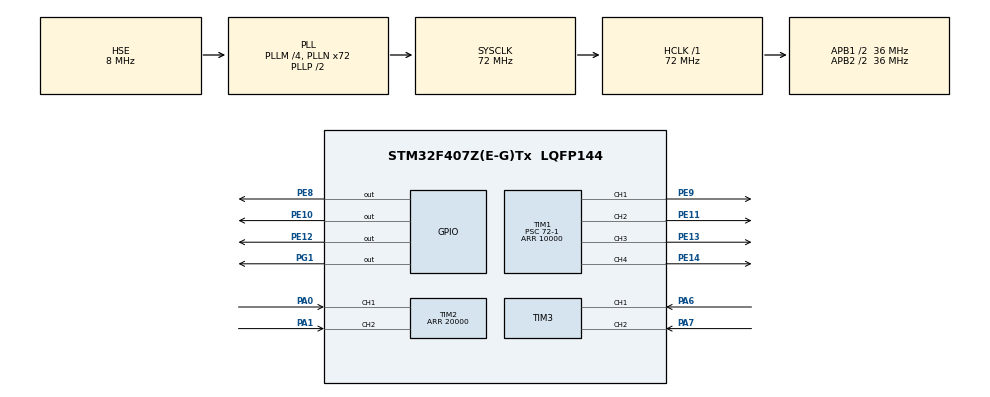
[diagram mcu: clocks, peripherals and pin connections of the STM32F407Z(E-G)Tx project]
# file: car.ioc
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Mcu.Family=STM32F4
Mcu.Name=STM32F407Z(E-G)Tx
Mcu.Package=LQFP144
NVIC.PriorityGroup=NVIC_PRIORITYGROUP_4
NVIC.TIM2_IRQn=true\:0\:0\:false\:false\:true\:true\:true\:true
NVIC.TIM6_DAC_IRQn=true\:1\:0\:true\:false\:true\:true\:true\:true
PA0-WKUP.Signal=S_TIM2_CH1_ETR
PA1.Signal=S_TIM2_CH2
PA13.Mode=Serial_Wire
PA13.Signal=SYS_JTMS-SWDIO
PA14.Mode=Serial_Wire
PA14.Signal=SYS_JTCK-SWCLK
PA6.Signal=S_TIM3_CH1
PA7.Signal=S_TIM3_CH2
PC14-OSC32_IN.Mode=LSE-External-Oscillator
PC14-OSC32_IN.Signal=RCC_OSC32_IN
PC15-OSC32_OUT.Mode=LSE-External-Oscillator
PC15-OSC32_OUT.Signal=RCC_OSC32_OUT
PE10.PinState=GPIO_PIN_SET
PE10.Signal=GPIO_Output
PE11.Signal=S_TIM1_CH2
PE12.PinState=GPIO_PIN_RESET
PE12.Signal=GPIO_Output
PE13.Signal=S_TIM1_CH3
PE14.Signal=S_TIM1_CH4
PE8.PinState=GPIO_PIN_RESET
PE8.Signal=GPIO_Output
PE9.Signal=S_TIM1_CH1
PG1.PinState=GPIO_PIN_SET
PG1.Signal=GPIO_Output
PH0-OSC_IN.Mode=HSE-External-Oscillator
PH0-OSC_IN.Signal=RCC_OSC_IN
PH1-OSC_OUT.Mode=HSE-External-Oscillator
PH1-OSC_OUT.Signal=RCC_OSC_OUT
ProjectManager.HeapSize=0x200
ProjectManager.StackSize=0x400
ProjectManager.TargetToolchain=MDK-ARM V5.32
RCC.48MHZClocksFreq_Value=36000000
RCC.AHBFreq_Value=72000000
RCC.APB1CLKDivider=RCC_HCLK_DIV2
RCC.APB1Freq_Value=36000000
RCC.APB1TimFreq_Value=72000000
RCC.APB2CLKDivider=RCC_HCLK_DIV2
RCC.APB2Freq_Value=36000000
RCC.APB2TimFreq_Value=72000000
RCC.CortexFreq_Value=72000000
RCC.HCLKFreq_Value=72000000
RCC.HSE_VALUE=8000000
RCC.HSI_VALUE=16000000
RCC.PLLM=4
RCC.PLLN=72
RCC.PLLSourceVirtual=RCC_PLLSOURCE_HSE
RCC.SYSCLKFreq_VALUE=72000000
RCC.SYSCLKSource=RCC_SYSCLKSOURCE_PLLCLK
RCC.VCOOutputFreq_Value=144000000
SH.S_TIM1_CH1.0=TIM1_CH1,Output Compare1 CH1
SH.S_TIM1_CH2.0=TIM1_CH2,Output Compare2 CH2
SH.S_TIM1_CH3.0=TIM1_CH3,Output Compare3 CH3
SH.S_TIM1_CH4.0=TIM1_CH4,Output Compare4 CH4
SH.S_TIM2_CH1_ETR.0=TIM2_CH1,Encoder_Interface
SH.S_TIM2_CH2.0=TIM2_CH2,Encoder_Interface
SH.S_TIM3_CH1.0=TIM3_CH1,Encoder_Interface
SH.S_TIM3_CH2.0=TIM3_CH2,Encoder_Interface
TIM1.Channel-Output\ Compare1\ CH1=TIM_CHANNEL_1
TIM1.Channel-Output\ Compare2\ CH2=TIM_CHANNEL_2
TIM1.Channel-Output\ Compare3\ CH3=TIM_CHANNEL_3
TIM1.Channel-Output\ Compare4\ CH4=TIM_CHANNEL_4
TIM1.Period=10000
TIM1.Prescaler=72-1
TIM2.Period=20000
TIM6.Period=10000-1
TIM6.Prescaler=72-1
VP_TIM6_VS_ClockSourceINT.Mode=Enable_Timer
board=custom

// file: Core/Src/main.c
/* USER CODE BEGIN Header */
/**
  ******************************************************************************
  * @file           : main.c
  * @brief          : Main program body
  ******************************************************************************
  * @attention
  *
  * Copyright (c) 2023 STMicroelectronics.
  * All rights reserved.
  *
  * This software is licensed under terms that can be found in the LICENSE file
  * in the root directory of this software component.
  * If no LICENSE file comes with this software, it is provided AS-IS.
  *
  ******************************************************************************
  */
/* USER CODE END Header */
#include "main.h"
#include "tim.h"
#include "gpio.h"

/* USER CODE BEGIN Includes */
#include "D:/robomaster/car/MDK-ARM/motor.h"
/* USER CODE END Includes */

void SystemClock_Config(void);

/* USER CODE BEGIN 0 */

void HAL_TIM_PeriodElapsedCallback(TIM_HandleTypeDef *htim){
	if(htim->Instance==htim6.Instance){
		int16_t pluse=COUNTERNUM-RELOADVALUE/2;
		motor.totalAngle=pluse+motor.loopNum*RELOADVALUE/2;
		motor.speed=(float)(motor.totalAngle-motor.lastAngle)/(4*13*RR)*6000;
		motor.lastAngle=motor.totalAngle;
	}
	else if(htim->Instance==htim2.Instance){
		if(COUNTERNUM<10000) motor.loopNum++;
		else if(COUNTERNUM>10000)  motor.loopNum--;
		__HAL_TIM_SetCounter(&htim2, 10000);
	}
}
/* USER CODE END 0 */

int main(void)
{

  /* MCU Configuration--------------------------------------------------------*/

  /* Reset of all peripherals, Initializes the Flash interface and the Systick. */
  HAL_Init();

  /* Configure the system clock */
  SystemClock_Config();

  /* Initialize all configured peripherals */
  MX_GPIO_Init();
  MX_TIM1_Init();
  MX_TIM2_Init();
  MX_TIM3_Init();
  MX_TIM6_Init();

  /* Infinite loop */
  while (1)
  {

  }
}

void SystemClock_Config(void)
{
  RCC_OscInitTypeDef RCC_OscInitStruct = {0};
  RCC_ClkInitTypeDef RCC_ClkInitStruct = {0};

  /** Configure the main internal regulator output voltage
  */
  __HAL_RCC_PWR_CLK_ENABLE();
  __HAL_PWR_VOLTAGESCALING_CONFIG(PWR_REGULATOR_VOLTAGE_SCALE1);

  /** Initializes the RCC Oscillators according to the specified parameters
  * in the RCC_OscInitTypeDef structure.
  */
  RCC_OscInitStruct.OscillatorType = RCC_OSCILLATORTYPE_HSE;
  RCC_OscInitStruct.HSEState = RCC_HSE_ON;
  RCC_OscInitStruct.PLL.PLLState = RCC_PLL_ON;
  RCC_OscInitStruct.PLL.PLLSource = RCC_PLLSOURCE_HSE;
  RCC_OscInitStruct.PLL.PLLM = 4;
  RCC_OscInitStruct.PLL.PLLN = 72;
  RCC_OscInitStruct.PLL.PLLP = RCC_PLLP_DIV2;
  RCC_OscInitStruct.PLL.PLLQ = 4;
  if (HAL_RCC_OscConfig(&RCC_OscInitStruct) != HAL_OK)
  {
    Error_Handler();
  }

  /** Initializes the CPU, AHB and APB buses clocks
  */
  RCC_ClkInitStruct.ClockType = RCC_CLOCKTYPE_HCLK|RCC_CLOCKTYPE_SYSCLK
                              |RCC_CLOCKTYPE_PCLK1|RCC_CLOCKTYPE_PCLK2;
  RCC_ClkInitStruct.SYSCLKSource = RCC_SYSCLKSOURCE_PLLCLK;
  RCC_ClkInitStruct.AHBCLKDivider = RCC_SYSCLK_DIV1;
  RCC_ClkInitStruct.APB1CLKDivider = RCC_HCLK_DIV2;
  RCC_ClkInitStruct.APB2CLKDivider = RCC_HCLK_DIV2;

  if (HAL_RCC_ClockConfig(&RCC_ClkInitStruct, FLASH_LATENCY_2) != HAL_OK)
  {
    Error_Handler();
  }
}

void Error_Handler(void)
{
  __disable_irq();
  while (1)
  {
  }
}
